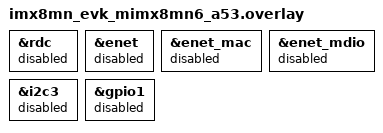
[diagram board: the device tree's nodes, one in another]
/*
 * Copyright 2024-2025 NXP
 *
 * SPDX-License-Identifier: BSD-3-Clause
 */

&rdc {
	status = "disabled";
};

&enet {
	status = "disabled";
};

&enet_mac {
	status = "disabled";
};

&enet_mdio {
	status = "disabled";
};

&i2c3 {
	status = "disabled";
};

&gpio1 {
	status = "disabled";
};
